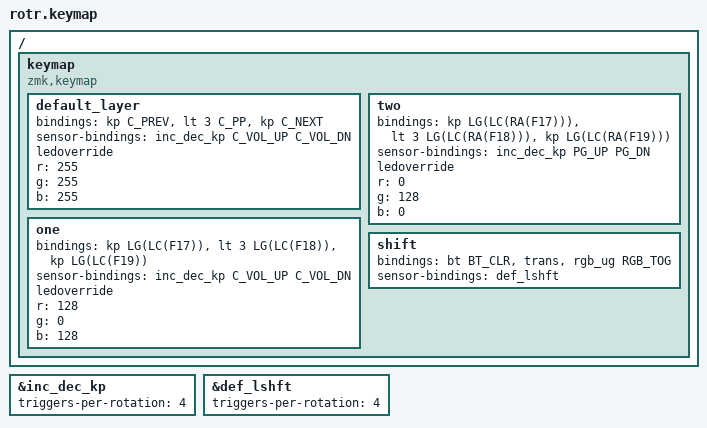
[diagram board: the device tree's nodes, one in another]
#include <behaviors.dtsi>
#include <dt-bindings/zmk/keys.h>
#include <dt-bindings/zmk/rgb.h>
#include <dt-bindings/zmk/bt.h>

&inc_dec_kp {
	triggers-per-rotation = <4>;
};
&def_lshft {
	triggers-per-rotation = <4>;
};

/ {
	keymap {
		compatible = "zmk,keymap";

		default_layer {
			//PREV | PLAY/PAUSE | NEXT | WHITE
			bindings = <&kp C_PREV &lt 3 C_PP &kp C_NEXT>;
			sensor-bindings = <&inc_dec_kp C_VOL_UP C_VOL_DN>;
			ledoverride;
			r = <255>;
			g = <255>;
			b = <255>;
		};
		one {
			//L CMD + L CTRL
			//F17 | F18 | F19 | PURPLE
			bindings = <&kp LG(LC(F17)) &lt 3 LG(LC(F18)) &kp LG(LC(F19))>;
			sensor-bindings = <&inc_dec_kp C_VOL_UP C_VOL_DN>;
			ledoverride;
			r = <128>;
			g = <0>;
			b = <128>;
		};
		two {
			//L CMD + L CTRL | R OPT
			//F17 | F18 | F19 | GREEN
			bindings = <&kp LG(LC(RA(F17))) &lt 3 LG(LC(RA(F18))) &kp LG(LC(RA(F19)))>;
			sensor-bindings = <&inc_dec_kp PG_UP PG_DN>;
			ledoverride;
			r = <0>;
			g = <128>;
			b = <0>;
		};
		shift {
			bindings = <&bt BT_CLR &trans &rgb_ug RGB_TOG>;
			sensor-bindings = <&def_lshft>;
		};
	};
};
